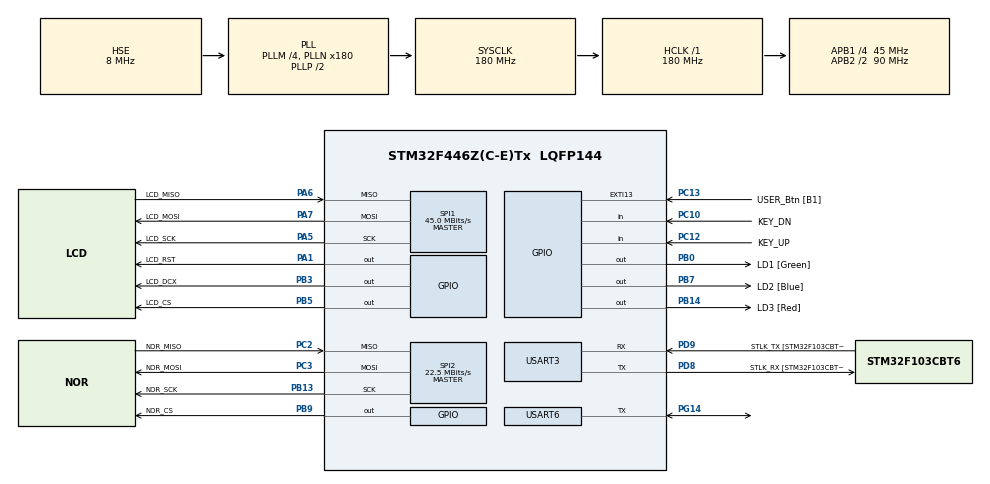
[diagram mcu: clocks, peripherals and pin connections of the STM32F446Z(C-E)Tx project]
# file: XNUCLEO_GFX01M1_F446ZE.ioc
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Dma.Request0=SPI1_TX
Dma.Request1=SPI2_RX
Dma.Request2=SPI2_TX
Dma.Request3=USART6_TX
Dma.Request4=USART6_RX
Dma.SPI1_TX.0.Direction=DMA_MEMORY_TO_PERIPH
Dma.SPI1_TX.0.FIFOMode=DMA_FIFOMODE_DISABLE
Dma.SPI1_TX.0.Instance=DMA2_Stream3
Dma.SPI1_TX.0.MemDataAlignment=DMA_MDATAALIGN_BYTE
Dma.SPI1_TX.0.MemInc=DMA_MINC_ENABLE
Dma.SPI1_TX.0.Mode=DMA_NORMAL
Dma.SPI1_TX.0.PeriphDataAlignment=DMA_PDATAALIGN_BYTE
Dma.SPI1_TX.0.PeriphInc=DMA_PINC_DISABLE
Dma.SPI1_TX.0.Priority=DMA_PRIORITY_MEDIUM
Dma.SPI2_RX.1.Direction=DMA_PERIPH_TO_MEMORY
Dma.SPI2_RX.1.FIFOMode=DMA_FIFOMODE_DISABLE
Dma.SPI2_RX.1.Instance=DMA1_Stream3
Dma.SPI2_RX.1.MemDataAlignment=DMA_MDATAALIGN_BYTE
Dma.SPI2_RX.1.MemInc=DMA_MINC_ENABLE
Dma.SPI2_RX.1.Mode=DMA_NORMAL
Dma.SPI2_RX.1.PeriphDataAlignment=DMA_PDATAALIGN_BYTE
Dma.SPI2_RX.1.PeriphInc=DMA_PINC_DISABLE
Dma.SPI2_RX.1.Priority=DMA_PRIORITY_HIGH
Dma.SPI2_TX.2.Direction=DMA_MEMORY_TO_PERIPH
Dma.SPI2_TX.2.FIFOMode=DMA_FIFOMODE_DISABLE
Dma.SPI2_TX.2.Instance=DMA1_Stream4
Dma.SPI2_TX.2.MemDataAlignment=DMA_MDATAALIGN_BYTE
Dma.SPI2_TX.2.MemInc=DMA_MINC_ENABLE
Dma.SPI2_TX.2.Mode=DMA_NORMAL
Dma.SPI2_TX.2.PeriphDataAlignment=DMA_PDATAALIGN_BYTE
Dma.SPI2_TX.2.PeriphInc=DMA_PINC_DISABLE
Dma.SPI2_TX.2.Priority=DMA_PRIORITY_HIGH
Dma.USART6_RX.4.Direction=DMA_PERIPH_TO_MEMORY
Dma.USART6_RX.4.FIFOMode=DMA_FIFOMODE_DISABLE
Dma.USART6_RX.4.Instance=DMA2_Stream1
Dma.USART6_RX.4.MemDataAlignment=DMA_MDATAALIGN_BYTE
Dma.USART6_RX.4.MemInc=DMA_MINC_ENABLE
Dma.USART6_RX.4.Mode=DMA_NORMAL
Dma.USART6_RX.4.PeriphDataAlignment=DMA_PDATAALIGN_BYTE
Dma.USART6_RX.4.PeriphInc=DMA_PINC_DISABLE
Dma.USART6_RX.4.Priority=DMA_PRIORITY_MEDIUM
Dma.USART6_TX.3.Direction=DMA_MEMORY_TO_PERIPH
Dma.USART6_TX.3.FIFOMode=DMA_FIFOMODE_DISABLE
Dma.USART6_TX.3.Instance=DMA2_Stream6
Dma.USART6_TX.3.MemDataAlignment=DMA_MDATAALIGN_BYTE
Dma.USART6_TX.3.MemInc=DMA_MINC_ENABLE
Dma.USART6_TX.3.Mode=DMA_NORMAL
Dma.USART6_TX.3.PeriphDataAlignment=DMA_PDATAALIGN_BYTE
Dma.USART6_TX.3.PeriphInc=DMA_PINC_DISABLE
Dma.USART6_TX.3.Priority=DMA_PRIORITY_LOW
Mcu.Family=STM32F4
Mcu.Name=STM32F446Z(C-E)Tx
Mcu.Package=LQFP144
NVIC.DMA1_Stream3_IRQn=true\:2\:0\:true\:false\:true\:false\:true\:true
NVIC.DMA1_Stream4_IRQn=true\:2\:0\:true\:false\:true\:false\:true\:true
NVIC.DMA2_Stream1_IRQn=true\:2\:0\:true\:false\:true\:false\:true\:true
NVIC.DMA2_Stream3_IRQn=true\:1\:0\:true\:false\:true\:false\:true\:true
NVIC.DMA2_Stream6_IRQn=true\:2\:0\:true\:false\:true\:false\:true\:true
NVIC.PriorityGroup=NVIC_PRIORITYGROUP_4
NVIC.SPI1_IRQn=true\:2\:0\:true\:false\:true\:true\:true\:true
NVIC.SPI2_IRQn=true\:0\:0\:false\:false\:true\:true\:true\:true
NVIC.TIM3_IRQn=true\:0\:0\:false\:false\:true\:true\:true\:true
NVIC.USART6_IRQn=true\:0\:0\:false\:false\:true\:true\:true\:true
PA1.GPIO_Label=LCD_RST
PA1.GPIO_Speed=GPIO_SPEED_FREQ_VERY_HIGH
PA1.PinState=GPIO_PIN_SET
PA1.Signal=GPIO_Output
PA13.GPIO_Label=TMS
PA13.Mode=Serial_Wire
PA13.Signal=SYS_JTMS-SWDIO
PA14.GPIO_Label=TCK
PA14.Mode=Serial_Wire
PA14.Signal=SYS_JTCK-SWCLK
PA5.GPIO_Label=LCD_SCK
PA5.Mode=Full_Duplex_Master
PA5.Signal=SPI1_SCK
PA6.GPIO_Label=LCD_MISO
PA6.Mode=Full_Duplex_Master
PA6.Signal=SPI1_MISO
PA7.GPIO_Label=LCD_MOSI
PA7.Mode=Full_Duplex_Master
PA7.Signal=SPI1_MOSI
PB0.GPIO_Label=LD1 [Green]
PB0.Signal=GPIO_Output
PB13.GPIO_Label=NOR_SCK
PB13.Mode=Full_Duplex_Master
PB13.Signal=SPI2_SCK
PB14.GPIO_Label=LD3 [Red]
PB14.Signal=GPIO_Output
PB3.GPIO_Label=LCD_DCX
PB3.GPIO_Speed=GPIO_SPEED_FREQ_VERY_HIGH
PB3.PinState=GPIO_PIN_SET
PB3.Signal=GPIO_Output
PB5.GPIO_Label=LCD_CS
PB5.GPIO_Speed=GPIO_SPEED_FREQ_VERY_HIGH
PB5.PinState=GPIO_PIN_SET
PB5.Signal=GPIO_Output
PB7.GPIO_Label=LD2 [Blue]
PB7.Signal=GPIO_Output
PB9.GPIO_Label=NOR_CS
PB9.GPIO_Speed=GPIO_SPEED_FREQ_VERY_HIGH
PB9.PinState=GPIO_PIN_SET
PB9.Signal=GPIO_Output
PC10.GPIO_Label=KEY_DN
PC10.Signal=GPIO_Input
PC12.GPIO_Label=KEY_UP
PC12.Signal=GPIO_Input
PC13.GPIO_Label=USER_Btn [B1]
PC13.Signal=GPXTI13
PC14-OSC32_IN.Mode=LSE-External-Oscillator
PC14-OSC32_IN.Signal=RCC_OSC32_IN
PC15-OSC32_OUT.Mode=LSE-External-Oscillator
PC15-OSC32_OUT.Signal=RCC_OSC32_OUT
PC2.GPIO_Label=NOR_MISO
PC2.Mode=Full_Duplex_Master
PC2.Signal=SPI2_MISO
PC3.GPIO_Label=NOR_MOSI
PC3.Mode=Full_Duplex_Master
PC3.Signal=SPI2_MOSI
PD8.GPIO_Label=STLK_RX [STM32F103CBT6_PA3]
PD8.Mode=Asynchronous
PD8.Signal=USART3_TX
PD9.GPIO_Label=STLK_TX [STM32F103CBT6_PA2]
PD9.Mode=Asynchronous
PD9.Signal=USART3_RX
PG14.Mode=Half_duplex(single_wire_mode)
PG14.Signal=USART6_TX
PH0-OSC_IN.GPIO_Label=MCO [STM32F103CBT6_PA8]
PH0-OSC_IN.Mode=HSE-External-Clock-Source
PH0-OSC_IN.Signal=RCC_OSC_IN
PH1-OSC_OUT.Mode=HSE-External-Clock-Source
PH1-OSC_OUT.Signal=RCC_OSC_OUT
ProjectManager.HeapSize=0x200
ProjectManager.StackSize=0x400
ProjectManager.TargetToolchain=STM32CubeIDE
RCC.48MHZClocksFreq_Value=24000000
RCC.AHBFreq_Value=180000000
RCC.APB1CLKDivider=RCC_HCLK_DIV4
RCC.APB1Freq_Value=45000000
RCC.APB1TimFreq_Value=90000000
RCC.APB2CLKDivider=RCC_HCLK_DIV2
RCC.APB2Freq_Value=90000000
RCC.APB2TimFreq_Value=180000000
RCC.CortexFreq_Value=180000000
RCC.HCLKFreq_Value=180000000
RCC.HSE_VALUE=8000000
RCC.HSI_VALUE=16000000
RCC.PLLM=4
RCC.PLLMUL=RCC_PLL_MUL9
RCC.PLLN=180
RCC.PLLQ=7
RCC.PLLSourceVirtual=RCC_PLLSOURCE_HSE
RCC.PRESCALERUSB=RCC_USBCLKSOURCE_PLL_DIV1_5
RCC.SYSCLKFreq_VALUE=180000000
RCC.SYSCLKSource=RCC_SYSCLKSOURCE_PLLCLK
RCC.SYSCLKSourceVirtual=RCC_SYSCLKSOURCE_PLLCLK
RCC.USBFreq_Value=51428571.428571425
RCC.VCOOutputFreq_Value=360000000
SPI1.CalculateBaudRate=45.0 MBits/s
SPI1.Direction=SPI_DIRECTION_2LINES
SPI1.Mode=SPI_MODE_MASTER
SPI1.VirtualType=VM_MASTER
SPI2.CalculateBaudRate=22.5 MBits/s
SPI2.Direction=SPI_DIRECTION_2LINES
SPI2.Mode=SPI_MODE_MASTER
SPI2.VirtualType=VM_MASTER
STMicroelectronics.X-CUBE-TOUCHGFX.4.24.1.ApplicationCcGraphicsJjApplication=TouchGFXOoGenerator
STMicroelectronics.X-CUBE-TOUCHGFX.4.24.1.tgfx_buffering_strategy=Partial
STMicroelectronics.X-CUBE-TOUCHGFX.4.24.1.tgfx_custom_height=240
STMicroelectronics.X-CUBE-TOUCHGFX.4.24.1.tgfx_custom_width=320
STMicroelectronics.X-CUBE-TOUCHGFX.4.24.1.tgfx_datareader=Enabled
STMicroelectronics.X-CUBE-TOUCHGFX.4.24.1_IsPackSelfContextualization=true
TIM3.Period=1399
TIM3.Prescaler=999
USART3.VirtualMode=VM_ASYNC
USART6.VirtualMode=VM_ASYNC
VP_CRC_VS_CRC.Mode=CRC_Activate
VP_STMicroelectronics.X-CUBE-TOUCHGFX_VS_GraphicsJjApplication_4.24.1.Mode=GraphicsJjApplication
VP_TIM3_VS_ClockSourceINT.Mode=Internal
board=NUCLEO-F446ZE

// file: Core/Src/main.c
/* USER CODE BEGIN Header */
/**
  ******************************************************************************
  * @file           : main.c
  * @brief          : Main program body
  ******************************************************************************
  * @attention
  *
  * Copyright (c) 2025 STMicroelectronics.
  * All rights reserved.
  *
  * This software is licensed under terms that can be found in the LICENSE file
  * in the root directory of this software component.
  * If no LICENSE file comes with this software, it is provided AS-IS.
  *
  ******************************************************************************
  */
/* USER CODE END Header */
#include "main.h"
#include "crc.h"
#include "dma.h"
#include "spi.h"
#include "tim.h"
#include "usart.h"
#include "gpio.h"
#include "app_touchgfx.h"

/* USER CODE BEGIN Includes */
#include "gfx01m1_lcd.h"
#include "mx25.h"
#include "ds18b20.h"
/* USER CODE END Includes */

void SystemClock_Config(void);

int main(void)
{

  /* USER CODE BEGIN 1 */
  uint32_t readid = 0;
  /* USER CODE END 1 */

  /* MCU Configuration--------------------------------------------------------*/

  /* Reset of all peripherals, Initializes the Flash interface and the Systick. */
  HAL_Init();

  /* Configure the system clock */
  SystemClock_Config();

  /* Initialize all configured peripherals */
  MX_GPIO_Init();
  MX_DMA_Init();
  MX_USART3_UART_Init();
  MX_SPI1_Init();
  MX_SPI2_Init();
  MX_TIM3_Init();
  MX_CRC_Init();
  MX_USART6_UART_Init();
  MX_TouchGFX_Init();
  /* USER CODE BEGIN 2 */
  __HAL_SPI_ENABLE(&hspi2);
  mx25_reset();
  readid = mx25_readid();

  gfx01m1_lcd_init();
  /* USER CODE END 2 */

  /* Infinite loop */
  while (1)
  {

  MX_TouchGFX_Process();
  }
}

void SystemClock_Config(void)
{
  RCC_OscInitTypeDef RCC_OscInitStruct = {0};
  RCC_ClkInitTypeDef RCC_ClkInitStruct = {0};

  /** Configure the main internal regulator output voltage
  */
  __HAL_RCC_PWR_CLK_ENABLE();
  __HAL_PWR_VOLTAGESCALING_CONFIG(PWR_REGULATOR_VOLTAGE_SCALE1);

  /** Initializes the RCC Oscillators according to the specified parameters
  * in the RCC_OscInitTypeDef structure.
  */
  RCC_OscInitStruct.OscillatorType = RCC_OSCILLATORTYPE_HSE;
  RCC_OscInitStruct.HSEState = RCC_HSE_BYPASS;
  RCC_OscInitStruct.PLL.PLLState = RCC_PLL_ON;
  RCC_OscInitStruct.PLL.PLLSource = RCC_PLLSOURCE_HSE;
  RCC_OscInitStruct.PLL.PLLM = 4;
  RCC_OscInitStruct.PLL.PLLN = 180;
  RCC_OscInitStruct.PLL.PLLP = RCC_PLLP_DIV2;
  RCC_OscInitStruct.PLL.PLLQ = 7;
  RCC_OscInitStruct.PLL.PLLR = 2;
  if (HAL_RCC_OscConfig(&RCC_OscInitStruct) != HAL_OK)
  {
    Error_Handler();
  }

  /** Activate the Over-Drive mode
  */
  if (HAL_PWREx_EnableOverDrive() != HAL_OK)
  {
    Error_Handler();
  }

  /** Initializes the CPU, AHB and APB buses clocks
  */
  RCC_ClkInitStruct.ClockType = RCC_CLOCKTYPE_HCLK|RCC_CLOCKTYPE_SYSCLK
                              |RCC_CLOCKTYPE_PCLK1|RCC_CLOCKTYPE_PCLK2;
  RCC_ClkInitStruct.SYSCLKSource = RCC_SYSCLKSOURCE_PLLCLK;
  RCC_ClkInitStruct.AHBCLKDivider = RCC_SYSCLK_DIV1;
  RCC_ClkInitStruct.APB1CLKDivider = RCC_HCLK_DIV4;
  RCC_ClkInitStruct.APB2CLKDivider = RCC_HCLK_DIV2;

  if (HAL_RCC_ClockConfig(&RCC_ClkInitStruct, FLASH_LATENCY_5) != HAL_OK)
  {
    Error_Handler();
  }
}

/* USER CODE BEGIN 4 */
extern void touchgfxSignalVSync(void);

void HAL_TIM_PeriodElapsedCallback(TIM_HandleTypeDef *htim)
{
	if (htim->Instance == TIM3)
	{
		touchgfxSignalVSync();
	}
}
/* USER CODE END 4 */

void Error_Handler(void)
{
  __disable_irq();
  while (1)
  {
  }
}
